CM_ "AUTOGENERATED FILE, DO NOT EDIT"

CM_ "Imported file _comma.dbc starts here"

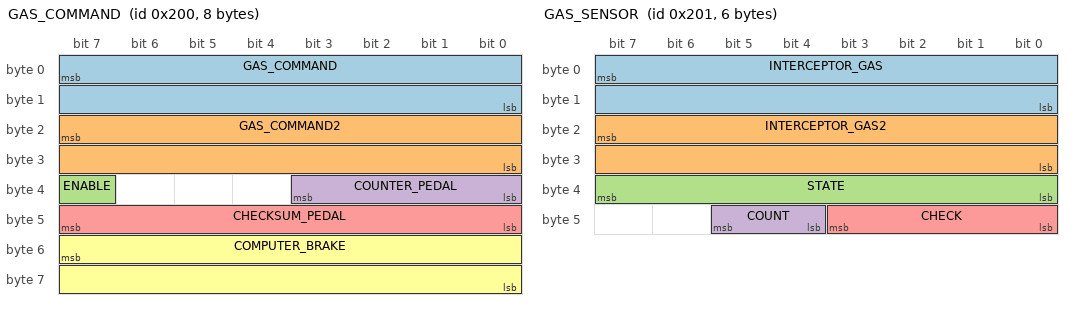
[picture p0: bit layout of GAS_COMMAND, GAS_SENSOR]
BO_ 512 GAS_COMMAND: 8 EON
 SG_ GAS_COMMAND : 7|16@0+ (0.253984064,-83.3) [0|1] "" INTERCEPTOR
 SG_ GAS_COMMAND2 : 23|16@0+ (0.126992032,-83.3) [0|1] "" INTERCEPTOR
 SG_ ENABLE : 39|1@0+ (1,0) [0|1] "" INTERCEPTOR
 SG_ COUNTER_PEDAL : 35|4@0+ (1,0) [0|15] "" INTERCEPTOR
 SG_ CHECKSUM_PEDAL : 47|8@0+ (1,0) [0|255] "" INTERCEPTOR
 SG_ COMPUTER_BRAKE : 55|16@0+ (0.005,1000) [0|65535] "" XXX

BO_ 513 GAS_SENSOR: 6 INTERCEPTOR
 SG_ INTERCEPTOR_GAS : 7|16@0+ (0.253984064,-83.3) [0|1] "" EON
 SG_ INTERCEPTOR_GAS2 : 23|16@0+ (0.126992032,-83.3) [0|1] "" EON
 SG_ STATE : 39|8@0+ (1,0) [0|255] "" EON
 SG_ COUNT : 45|2@0+ (1,0) [0|3] "" EON
 SG_ CHECK : 43|4@0+ (1,0) [0|3] "" EON

BO_ 0 RIEN: 6 RIEN

VAL_ 513 STATE 5 "FAULT_TIMEOUT" 4 "FAULT_STARTUP" 3 "FAULT_SCE" 2 "FAULT_SEND" 1 "FAULT_BAD_CHECKSUM" 0 "NO_FAULT" ;

CM_ "Imported file _honda_2017.dbc starts here"
VERSION ""

NS_ :

BU_: PCM MACC ABS EPS EON ADAS XXX

BO_ 228 STEERING_CONTROL: 5 ADAS
 SG_ STEER_TORQUE : 7|16@0+ (1,0) [0|65535] "" EPS
 SG_ LKAS_ACTIVE : 16|1@0+ (1,0) [0|1] "" EPS
 SG_ LK_MODE : 20|1@0+ (1,0) [0|1] "" EPS
 SG_ ST_NOT_ALL : 24|1@0+ (1,0) [0|1] "" EPS
 SG_ ANGLE_DES : 39|16@0+ (1,0) [0|65535] "deg" EPS

BO_ 198 STEERING_SENSORS: 8 PCM
 SG_ STEER_ANGLE_RATE : 23|16@0+ (0.1,-3276.8) [0|65535] "deg/s" XXX
 SG_ STEER_ANGLE : 7|16@0+ (0.1,-3276.8) [0|65535] "deg" XXX

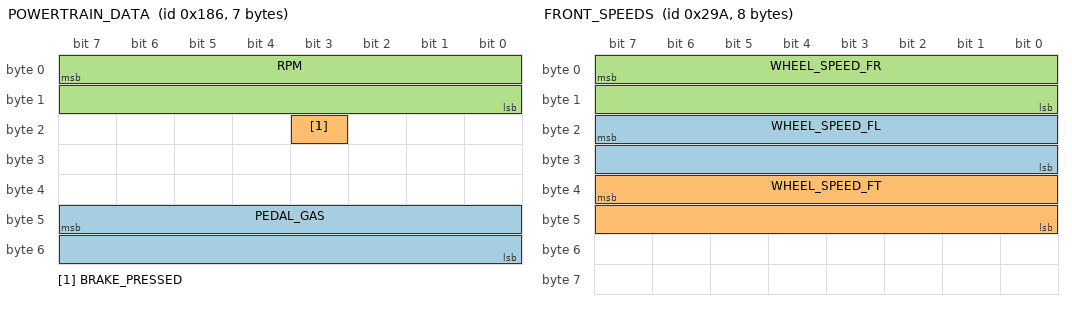
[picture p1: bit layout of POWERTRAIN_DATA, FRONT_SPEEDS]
BO_ 390 POWERTRAIN_DATA: 7 PCM
 SG_ PEDAL_GAS : 47|16@0+ (1,0) [0|65535] "" XXX
 SG_ BRAKE_PRESSED : 19|1@0+ (1,0) [0|1] "" XXX
 SG_ RPM : 7|16@0+ (0.1,0) [0|65535] "rpm" XXX

BO_ 502 BRAKE: 8 PCM
 SG_ BRAKE_PRESSED : 19|1@0+ (1,0) [0|1] "" XXX

BO_ 666 FRONT_SPEEDS: 8 PCM
 SG_ WHEEL_SPEED_FL : 23|16@0+ (0.005,0) [0|65535] "kmh" XXX
 SG_ WHEEL_SPEED_FT : 39|16@0+ (0.005,0) [0|65535] "kmh" XXX
 SG_ WHEEL_SPEED_FR : 7|16@0+ (0.005,0) [0|65535] "kmh" XXX

BO_ 668 REAR_SPEEDS: 8 PCM
 SG_ WHEEL_SPEED_RL : 7|16@0+ (0.005,0) [0|65535] "kmh" XXX
 SG_ WHEEL_SPEED_RR : 23|16@0+ (0.005,0) [0|65535] "kmh" XXX

BO_ 679 SPEEDS: 8 XXX
 SG_ SPEED1 : 7|16@0+ (0.005,0) [0|65535] "" XXX
 SG_ SPEED2 : 23|16@0+ (0.005,0) [0|65535] "" XXX

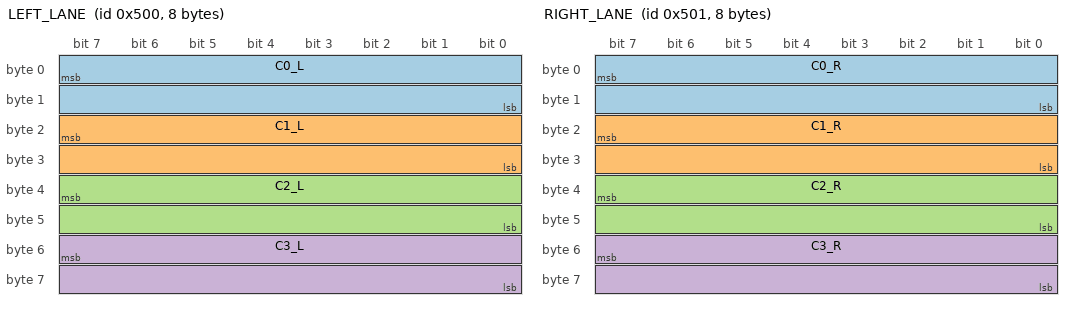
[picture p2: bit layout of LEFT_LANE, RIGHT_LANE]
BO_ 1280 LEFT_LANE: 8 XXX
 SG_ C0_L : 7|16@0+ (0.005,1000) [0|65535] "" XXX
 SG_ C1_L : 23|16@0+ (0.005,1000) [0|65535] "" XXX
 SG_ C2_L : 39|16@0+ (0.005,1000) [0|65535] "" XXX
 SG_ C3_L : 55|16@0+ (0.005,1000) [0|65535] "" XXX

BO_ 1281 RIGHT_LANE: 8 XXX
 SG_ C0_R : 7|16@0+ (0.005,1000) [0|65535] "" XXX
 SG_ C1_R : 23|16@0+ (0.005,1000) [0|65535] "" XXX
 SG_ C2_R : 39|16@0+ (0.005,1000) [0|65535] "" XXX
 SG_ C3_R : 55|16@0+ (0.005,1000) [0|65535] "" XXX

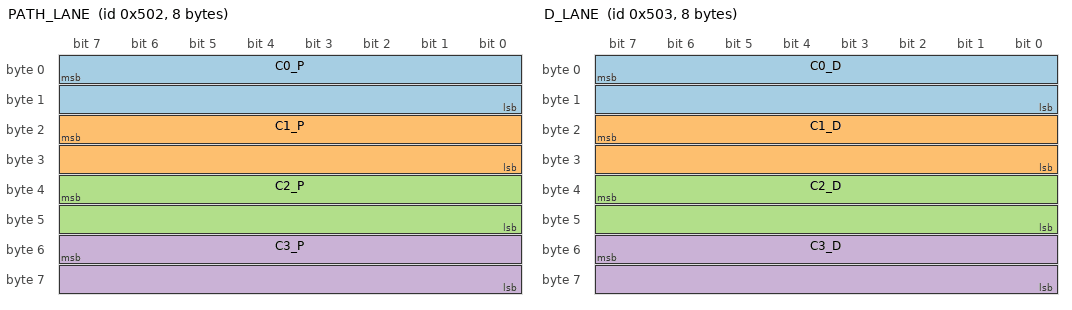
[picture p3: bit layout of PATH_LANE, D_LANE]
BO_ 1282 PATH_LANE: 8 XXX
 SG_ C0_P : 7|16@0+ (0.005,1000) [0|65535] "" XXX
 SG_ C1_P : 23|16@0+ (0.005,1000) [0|65535] "" XXX
 SG_ C2_P : 39|16@0+ (0.005,1000) [0|65535] "" XXX
 SG_ C3_P : 55|16@0+ (0.005,1000) [0|65535] "" XXX

BO_ 1283 D_LANE: 8 XXX
 SG_ C0_D : 7|16@0+ (0.005,1000) [0|65535] "" XXX
 SG_ C1_D : 23|16@0+ (0.005,1000) [0|65535] "" XXX
 SG_ C2_D : 39|16@0+ (0.005,1000) [0|65535] "" XXX
 SG_ C3_D : 55|16@0+ (0.005,1000) [0|65535] "" XXX

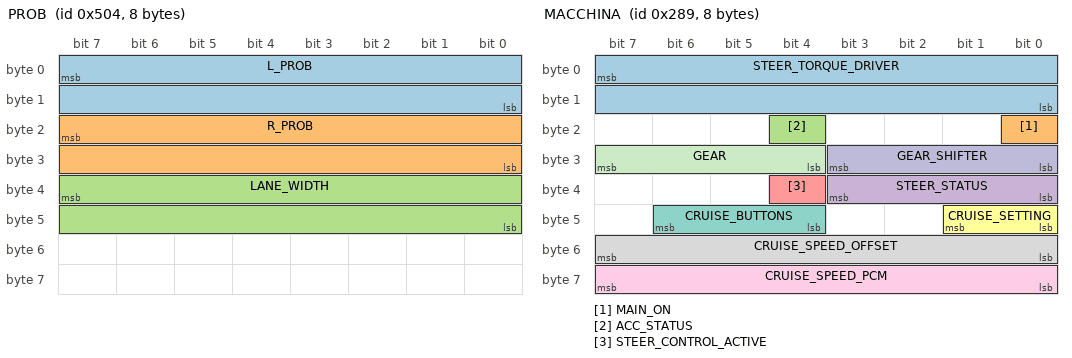
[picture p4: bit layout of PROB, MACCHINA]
BO_ 1284 PROB: 8 XXX
 SG_ L_PROB : 7|16@0+ (0.005,1000) [0|65535] "" XXX
 SG_ R_PROB : 23|16@0+ (0.005,1000) [0|65535] "" XXX
 SG_ LANE_WIDTH : 39|16@0+ (0.005,1000) [0|65535] "" XXX

BO_ 1285 PARAMS: 8 XXX
 SG_ AO_OFFSET : 7|12@0+ (0.01,2048) [0|4095] "" XXX
 SG_ AO_OFFSET_AV : 19|12@0+ (0.01,2048) [0|4095] "" XXX
 SG_ STIFFNESS : 31|12@0+ (0.01,2048) [0|4095] "" XXX
 SG_ STEER_RATIO : 43|12@0+ (0.01,2048) [0|4095] "" XXX
 SG_ CURV_FACTOR : 55|12@0+ (0.005,2048) [0|4095] "" XXX

BO_ 1286 MPC: 8 XXX
 SG_ VAL_X : 7|16@0+ (0.01,1000) [0|65535] "" XXX
 SG_ VAL_Y : 23|16@0+ (0.01,1000) [0|65535] "" XXX
 SG_ PSI : 39|16@0+ (0.005,1000) [0|65535] "" XXX
 SG_ DELTA : 55|16@0+ (0.005,1000) [0|65535] "" XXX
 SG_ COST : 55|16@0+ (0.005,1000) [0|65535] "" XXX

BO_ 649 MACCHINA: 8 MACC
 SG_ STEER_TORQUE_DRIVER : 7|16@0- (1,0) [-31000|31000] "" EON
 SG_ MAIN_ON : 16|1@0+ (1,0) [0|1] "" EON
 SG_ ACC_STATUS : 20|1@0+ (1,0) [0|1] "" EON
 SG_ STEER_STATUS : 35|4@0+ (1,0) [0|15] "" EON
 SG_ STEER_CONTROL_ACTIVE : 36|1@0+ (1,0) [0|1] "" EON
 SG_ CRUISE_SETTING : 41|2@0+ (1,0) [0|3] "" EON
 SG_ CRUISE_BUTTONS : 46|3@0+ (1,0) [0|7] "" EON
 SG_ CRUISE_SPEED_OFFSET : 55|8@0- (0.1,0) [-128|127] "kmh" EON
 SG_ CRUISE_SPEED_PCM : 63|8@0+ (1,0) [0|255] "kmh" EON
 SG_ GEAR_SHIFTER : 24|4@1+ (1,0) [0|15] "" EON
 SG_ GEAR : 31|4@0+ (1,0) [0|15] "" EON

VAL_ 649 GEAR_SHIFTER 32 "L" 16 "S" 8 "D" 4 "N" 2 "R" 1 "P" ;
VAL_ 649 GEAR 7 "L" 10 "S" 4 "D" 3 "N" 2 "R" 1 "P" ;
VAL_ 649 CRUISE_BUTTONS 7 "tbd" 6 "tbd" 5 "tbd" 4 "accel_res" 3 "decel_set" 2 "cancel" 1 "main" 0 "none" ;
VAL_ 649 CRUISE_SETTING 3 "distance_adj" 2 "tbd" 1 "lkas_button" 0 "none" ;
